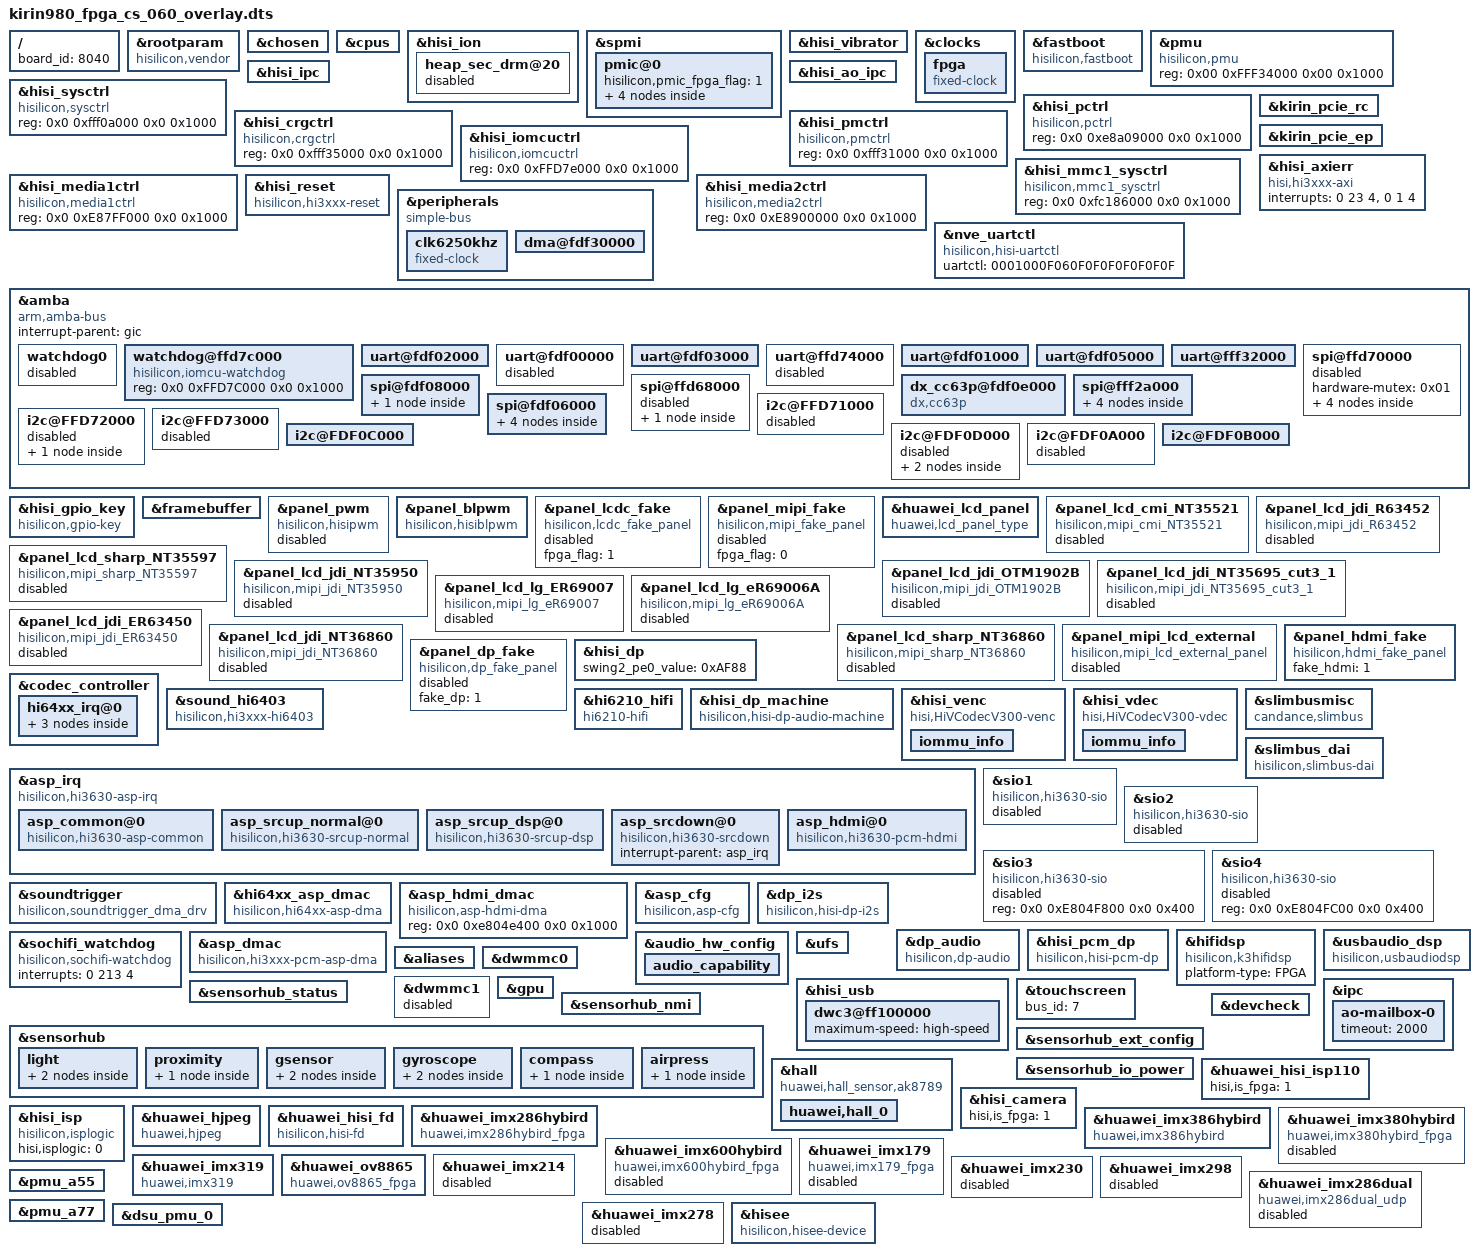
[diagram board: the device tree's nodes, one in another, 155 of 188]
/**
 * Copyright (C) 2014 Hisilicon Ltd.
 *
 *  This program is free software; you can redistribute it and/or modify
 *  it under the terms of the GNU General Public License version 2 as
 *  publishhed by the Free Software Foundation.
 */

/dts-v1/;
/plugin/;
/include/ "kirin980_fpga_cs_060_pin.dtsi"
/include/ "kirin980_fpga_cs_060_modem_pin.dtsi"
/include/ "kirin980_fpga_cs_060_hi6402_pin.dtsi"

/ {
    board_id = <8040>;
};

	&rootparam{
		compatible = "hisilicon,vendor";
		hisi,boardid = <8 0 4 0>;
		hisi,boardname = "kirin980_fpga_cs_060";
		hisi,modem_id = <0x37F5FC00>;
		hisi,product_id = <0x37F5FC10>;
	};

	&chosen{};


	&cpus {
	};

	&hisi_ion {
		heap_sec_drm@20 {
			status = "disabled";
		};
	};

	&spmi {
		pmic@0 {
			hisilicon,pmic_fpga_flag=<1>;
				pmic_led@a0 {
					status = "ok";
				};
				pmic_rtc@a0 {
			       		status = "disabled";
				};
				ponkey@b1{
		           		status = "ok";
				};
				pmic_mntn@a0 {
					status = "disabled";
				};
		};
	};
	&hisi_vibrator {
		status = "ok";
	};

	&clocks {
		fpga {
			compatible = "fixed-clock";
			#clock-cells = <0>;
			clock-frequency = <19200000>;
			clock-output-names = "fpga";
		};
	};

	&fastboot {
		compatible = "hisilicon,fastboot";
		i2c3-pin = <0>;
		gpio-keyup = <147>;
		gpio-keydown = <146>;
		uart-board-type = <1>;
		/*UDP_TYPE 0,PRODUCT 1,FPGA 2,EMU 3*/
		lpm3-board-type = <2>;
		jtagtosd-board-type = <2>;
		motor-vib_type = <0>;

		i2c-select = <1>;
		i2c-sel0-gpio = <164>;
		i2c-sel1-gpio = <165>;
		i2c-sel0-val = <0>;
		i2c-sel1-val = <0>;
	};

	&pmu {
		compatible = "hisilicon,pmu";
		reg = <0x00 0xFFF34000 0x00 0x1000>;
		status = "ok";
	};

	&hisi_ipc {

	};
	&hisi_ao_ipc {

	};

        &hisi_sysctrl {
                compatible = "hisilicon,sysctrl";
                reg = <0x0 0xfff0a000 0x0 0x1000>;
                status = "ok";
        };

        &hisi_pctrl {
                compatible = "hisilicon,pctrl";
                reg = <0x0 0xe8a09000 0x0 0x1000>;
                status = "ok";
        };

        &hisi_crgctrl {
                compatible = "hisilicon,crgctrl";
                reg = <0x0 0xfff35000 0x0 0x1000>;
                status = "ok";
        };

	&hisi_iomcuctrl {
                compatible = "hisilicon,iomcuctrl";
                reg = <0x0 0xFFD7e000 0x0 0x1000>;
                status = "ok";
        };

        &hisi_pmctrl {
                compatible = "hisilicon,pmctrl";
                reg = <0x0 0xfff31000 0x0 0x1000>;
                status = "ok";
        };

        &hisi_mmc1_sysctrl {
                compatible = "hisilicon,mmc1_sysctrl";
                reg = <0x0 0xfc186000 0x0 0x1000>;
                status = "ok";
        };

        &hisi_media1ctrl {
                compatible = "hisilicon,media1ctrl";
                reg = <0x0 0xE87FF000 0x0 0x1000>;
                status = "ok";
        };

        &hisi_media2ctrl {
                compatible = "hisilicon,media2ctrl";
                reg = <0x0 0xE8900000 0x0 0x1000>;
                status = "ok";
        };

	&kirin_pcie_rc {
		wl_power = <63>;

		/* param from EP: for BCM43596  */
		ep_ltr_latency = <0x10031003>;
		ep_l1ss_ctrl2 = <0x61>;
		l1ss_ctrl1 = <0x4004370F>;
		t_ref2perst = <21000 23000>;
		t_perst2access = <7000 8000>;
		t_perst2rst = <10000 11000>;
	};


	&kirin_pcie_ep {
		wl_power = <63>;

		/* param from EP: for BCM43596  */
		ep_ltr_latency = <0x10031003>;
		ep_l1ss_ctrl2 = <0x61>;
		l1ss_ctrl1 = <0x4004370F>;
		t_ref2perst = <21000 23000>;
		t_perst2access = <7000 8000>;
		t_perst2rst = <10000 11000>;
	};

	&hisi_axierr {
	        compatible = "hisi,hi3xxx-axi";
	        interrupts = <0 23 4>, <0 1 4>;
	        status = "ok";
        };

    &hisi_reset {
            compatible = "hisilicon,hi3xxx-reset";
            status = "ok";
        };

	&peripherals {
		compatible = "simple-bus";
		#address-cells = <1>;
		#size-cells = <1>;
		ranges = <0x0 0x00000000 0x0 0xffffffff>;

		clk6250khz {
			compatible = "fixed-clock";
			#clock-cells = <0>;
			clock-frequency = <6297600>;
			clock-output-names = "clk6250khz";
		};
/*
		clk4800khz {
			compatible = "fixed-clock";
			#clock-cells = <0>;
			clock-frequency = <32768>;
			clock-output-names = "clk4800khz";
		};
*/

		dma@fdf30000 {
			status = "ok";
		};


	};
	&nve_uartctl {
		compatible = "hisilicon,hisi-uartctl";
		uartctl = "0001000F060F0F0F0F0F0F0F";
	};
	&amba {
		#address-cells = <2>;
		#size-cells = <2>;
		compatible = "arm,amba-bus";
		interrupt-parent = <&gic>;
		ranges;

		/*rtc@FFF04000 {
				compatible = "arm,rtc-pl031", "arm,primecell";
				reg = <0xfff04000 0x1000>;
				interrupts = <0 46 0x4>;
				clocks = <&pclk>;
				clock-names = "apb_pclk";
				status = "ok";
		};*/

		/*rtc@FFF05000 {
				compatible = "arm,rtc-pl031", "arm,primecell";
				reg = <0xfff05000 0x1000>;
				interrupts = <0 47 0x4>;
				clocks = <&pclk>;
				clock-names = "apb_pclk";
				status = "ok";
		};*/

		watchdog0 {
			status = "disabled";
		};

                watchdog@ffd7c000{
                        compatible = "hisilicon,iomcu-watchdog";
                        reg = <0x0 0xFFD7C000 0x0 0x1000>;
                        status = "ok";
                };

		/*wdt1@e8a07000 {
			compatible = "arm,sp805", "arm,primecell";
			reg = <0x0 0xe8a07000 0x0 0x1000>;
			interrupts = <0 45 4>;
			clocks = <&pclk_gate_wd0 &pclk>;
			clock-names = "pclk_wd0", "apb_pclk";
		};*/

		uart@fdf02000 {
			pinctrl-names = "default", "idle";
			pinctrl-0 = <>;
			pinctrl-1 = <>;
			dma-names = "", "";
			dmas = <>;
			status = "ok";
		};

		uart@fdf00000 {
			pinctrl-names = "default", "idle";
			pinctrl-0 = <>;
			pinctrl-1 = <>;
			reset-enable-flag = <1>;
			status = "disabled";
		};

		uart@fdf03000 {
			pinctrl-names = "default", "idle";
			pinctrl-0 = <>;
			pinctrl-1 = <>;
			reset-enable-flag = <1>;
			status = "ok";
		};

		uart@ffd74000 {
			pinctrl-names = "default", "idle";
			pinctrl-0 = <>;
			pinctrl-1 = <>;
			status = "disabled";
			reset-enable-flag = <0>;
		};

		uart@fdf01000 {
			pinctrl-names = "default", "idle";
			pinctrl-0 = <>;
			pinctrl-1 = <>;
			status = "ok";
			reset-enable-flag = <1>;
		};

		uart@fdf05000 {
			pinctrl-names = "default", "idle";
			pinctrl-0 = <>;
			pinctrl-1 = <>;
			status = "ok";
			reset-enable-flag = <1>;
		};

		uart@fff32000 {
			pinctrl-names = "default", "idle";
			pinctrl-0 = <>;
			pinctrl-1 = <>;
			status = "ok";
		};

		dx_cc63p@fdf0e000 {
			compatible = "dx,cc63p";
			reg = <0x0 0xfdf0e000 0x0 0x1000>;
			interrupt-parent = <&gic>;
			interrupts = <0 135 4>;
			status = "ok";
		};

		spi@ffd70000 {
			status = "disabled";
			hardware-mutex = <0x01>;
			spi_dev0@0 {
					compatible = "spi_dev0";
					spi-max-frequency = <100000>;
					reg = <0>;
					pl022,com-mode = <0>;
					pl022,interface = <0>;
					pl022,rx-level-trig = <3>;
					pl022,tx-level-trig = <3>;
					pl022,ctrl-len = <7>;
					pl022,wait-state = <0>;
					pl022,duplex = <0>;
					pl022,slave-tx-disable = <0>;
			};

			spi_dev1@1 {
					compatible = "spi_dev1";
					spi-max-frequency = <13000000>;
					reg = <1>;
					pl022,com-mode = <1>;
					pl022,interface = <0>;
					pl022,rx-level-trig = <3>;
					pl022,tx-level-trig = <3>;
					pl022,ctrl-len = <7>;
					pl022,wait-state = <0>;
					pl022,duplex = <0>;
					pl022,slave-tx-disable = <0>;
			};

			spi_dev2@2 {
					compatible = "spi_dev2";
					spi-max-frequency = <13000000>;
					reg = <2>;
					pl022,com-mode = <2>;
					pl022,interface = <0>;
					pl022,rx-level-trig = <3>;
					pl022,tx-level-trig = <3>;
					pl022,ctrl-len = <7>;
					pl022,wait-state = <0>;
					pl022,duplex = <0>;
					pl022,slave-tx-disable = <0>;
			};

			spi_dev3@3 {
					compatible = "spi_dev3";
					spi-max-frequency = <13000000>;
					reg = <3>;
					pl022,com-mode = <0>;
					pl022,interface = <0>;
					pl022,rx-level-trig = <3>;
					pl022,tx-level-trig = <3>;
					pl022,ctrl-len = <7>;
					pl022,wait-state = <0>;
					pl022,duplex = <0>;
					pl022,slave-tx-disable = <0>;
			};
		};

		spi@fdf08000 {
			status = "ok";
			spi_dev10@10 {
					compatible = "spi_dev10";
					spi-max-frequency = <100000>;
					reg = <0>;
					pl022,com-mode = <0>;
					pl022,interface = <0>;
					pl022,rx-level-trig = <3>;
					pl022,tx-level-trig = <3>;
					pl022,ctrl-len = <7>;
					pl022,wait-state = <0>;
					pl022,duplex = <0>;
					pl022,slave-tx-disable = <0>;
			};
		};
		spi@ffd68000 {
			status = "disabled";
			spi_dev20@20 {
					compatible = "spi_dev20";
					spi-max-frequency = <100000>;
					reg = <0>;
					pl022,com-mode = <1>;
					pl022,interface = <0>;
					pl022,rx-level-trig = <3>;
					pl022,tx-level-trig = <3>;
					pl022,ctrl-len = <7>;
					pl022,wait-state = <0>;
					pl022,duplex = <0>;
					pl022,slave-tx-disable = <0>;
			};
		};

		spi@fff2a000 {
			status = "ok";
			spi_dev30@30 {
					compatible = "spi_dev30";
					spi-max-frequency = <100000>;
					reg = <0>;
					pl022,com-mode = <0>;
					pl022,interface = <0>;
					pl022,rx-level-trig = <3>;
					pl022,tx-level-trig = <3>;
					pl022,ctrl-len = <7>;
					pl022,wait-state = <0>;
					pl022,duplex = <0>;
					pl022,slave-tx-disable = <0>;
			};

			spi_dev31@31 {
					compatible = "spi_dev31";
					spi-max-frequency = <13000000>;
					reg = <1>;
					pl022,com-mode = <1>;
					pl022,interface = <0>;
					pl022,rx-level-trig = <3>;
					pl022,tx-level-trig = <3>;
					pl022,ctrl-len = <7>;
					pl022,wait-state = <0>;
					pl022,duplex = <0>;
					pl022,slave-tx-disable = <0>;
			};

			spi_dev32@32 {
					compatible = "spi_dev32";
					spi-max-frequency = <13000000>;
					reg = <2>;
					pl022,com-mode = <2>;
					pl022,interface = <0>;
					pl022,rx-level-trig = <3>;
					pl022,tx-level-trig = <3>;
					pl022,ctrl-len = <7>;
					pl022,wait-state = <0>;
					pl022,duplex = <0>;
					pl022,slave-tx-disable = <0>;
			};

			spi_dev33@33 {
					compatible = "spi_dev33";
					spi-max-frequency = <13000000>;
					reg = <3>;
					pl022,com-mode = <0>;
					pl022,interface = <0>;
					pl022,rx-level-trig = <3>;
					pl022,tx-level-trig = <3>;
					pl022,ctrl-len = <7>;
					pl022,wait-state = <0>;
					pl022,duplex = <0>;
					pl022,slave-tx-disable = <0>;
			};
		};
		spi@fdf06000 {
			status = "ok";
			spi_dev40@40 {
					compatible = "spi_dev40";
					spi-max-frequency = <100000>;
					reg = <0>;
					pl022,com-mode = <0>;
					pl022,interface = <0>;
					pl022,rx-level-trig = <3>;
					pl022,tx-level-trig = <3>;
					pl022,ctrl-len = <7>;
					pl022,wait-state = <0>;
					pl022,duplex = <0>;
					pl022,slave-tx-disable = <0>;
			};

			spi_dev41@41 {
					compatible = "spi_dev41";
					spi-max-frequency = <13000000>;
					reg = <1>;
					pl022,com-mode = <1>;
					pl022,interface = <0>;
					pl022,rx-level-trig = <3>;
					pl022,tx-level-trig = <3>;
					pl022,ctrl-len = <7>;
					pl022,wait-state = <0>;
					pl022,duplex = <0>;
					pl022,slave-tx-disable = <0>;
			};

			spi_dev42@42 {
					compatible = "spi_dev42";
					spi-max-frequency = <13000000>;
					reg = <2>;
					pl022,com-mode = <2>;
					pl022,interface = <0>;
					pl022,rx-level-trig = <3>;
					pl022,tx-level-trig = <3>;
					pl022,ctrl-len = <7>;
					pl022,wait-state = <0>;
					pl022,duplex = <0>;
					pl022,slave-tx-disable = <0>;
			};

			spi_dev43@43 {
					compatible = "spi_dev43";
					spi-max-frequency = <13000000>;
					reg = <3>;
					pl022,com-mode = <0>;
					pl022,interface = <0>;
					pl022,rx-level-trig = <3>;
					pl022,tx-level-trig = <3>;
					pl022,ctrl-len = <7>;
					pl022,wait-state = <0>;
					pl022,duplex = <0>;
					pl022,slave-tx-disable = <0>;
			};
		};
		/* I2C0 ~ I2C4 */
		i2c@FFD71000 {
			status = "disabled";
			pinctrl-names = "default", "idle";
			pinctrl-0 = <>;
			pinctrl-1 = <>;
			//cs-gpios = <>, <>;
		};

		i2c@FFD72000 {
			status = "disabled";
			clock-rate = <0 32000000>;
			pinctrl-names = "default", "idle";
			pinctrl-0 = <>;
			pinctrl-1 = <>;
			//cs-gpios = <>, <>;

			hisi,ncp6925@50{
				compatible = "hisi,ncp6925";
				reg = <0x50>;
				hisi,pmic_name = "ncp6925";
				hisi,pmic_index = <0>;
				hisi,slave_address = <0x50>;
				hisi,pmic-pin = <999 999 999>;
				hisi,pmic-voltage = <0x0 0x1 0x2 0x3 0x4 0x5 0x6>;
				hisi,pmic_ex_func_disable = <1>;
				status = "disabled";
			};
		};

		i2c@FFD73000 {
			status = "disabled";
			clock-rate = <0 32000000>;
			pinctrl-names = "default", "idle";
			pinctrl-0 = <>;
			pinctrl-1 = <>;
			//cs-gpios = <>, <>;
		};

		i2c@FDF0C000 {
			status = "ok";
			clock-rate = <0 20000000>;
			pinctrl-names = "default", "idle";
			pinctrl-0 = <>;
			pinctrl-1 = <>;
			//cs-gpios = <>, <>;
		};

		i2c@FDF0D000 {
			status = "disabled";
			clock-rate = <0 107000000>;
			pinctrl-names = "default", "idle";
			pinctrl-0 = <>;
			pinctrl-1 = <>;
			//cs-gpios = <>, <>;

			smartpa@31 {
				status = "ok";
				gain_incall = <0x16>;
				gain = <0x16>;
			};

			smartpa@34 {
				status = "ok";
				gain_incall = <0x16>;
				gain = <0x16>;
			};

		};

		i2c@FDF0A000 {
			status = "disabled";
			clock-rate = <0 107000000>;
			pinctrl-names = "default", "idle";
			pinctrl-0 = <>;
			pinctrl-1 = <>;
			//cs-gpios = <>, <>;
		};

		i2c@FDF0B000 {
			status = "ok";
			clock-rate = <0 107000000>;
			pinctrl-names = "default", "idle";
			pinctrl-0 = <&gpio191_pmx_func &gpio192_pmx_func &gpio191_cfg_func &gpio192_cfg_func>;
			pinctrl-1 = <&gpio191_pmx_idle &gpio192_pmx_idle &gpio191_cfg_idle &gpio192_cfg_idle>;
			cs-gpios = <&gpio23 7 0>, <&gpio24 0 0>;
		};
	};
	/* end amba */

	&hisi_gpio_key {
		compatible = "hisilicon,gpio-key";
		pinctrl-names = "default", "idle";
		pinctrl-0 = <>;
		pinctrl-1 = <>;
		gpio-keyup,gpio-irq = <&gpio18 3 0>;
		gpio-keydown,gpio-irq = <&gpio18 2 0>;
		status = "ok";
	};

	/* display start */
	&framebuffer {
		fpga_flag = <1>;
		//FB_ACCEL_KIRIN970_ES  0x20;FB_ACCEL_KIRIN970  0x40;
		dss_version_tag = <0x100>;
	};

	&panel_pwm {
		#address-cells = <2>;
		#size-cells = <2>;
		compatible = "hisilicon,hisipwm";
		reg = <0 0xE8A04000 0 0x1000>;
		clocks = <&clk_gate_pwm>;
		clock-names = "clk_pwm";
		//pinctrl-names = "default","idle";
		//pinctrl-0 = <&gpio182_pmx_func &gpio182_cfg_func>;
		//pinctrl-1 = <&gpio182_pmx_idle &gpio182_cfg_idle>;
		fpga_flag = <1>;
		status = "disabled";
	};

	&panel_blpwm {
		#address-cells = <2>;
		#size-cells = <2>;
		compatible = "hisilicon,hisiblpwm";
		reg = <0 0xFFD75000 0 0x1000>;
		clocks = <&clk_gate_blpwm>;
		clock-names = "clk_blpwm";
		pinctrl-names = "default","idle";
		pinctrl-0 = <&gpio181_pmx_func &gpio182_pmx_func &gpio181_cfg_func &gpio182_cfg_func>;
		pinctrl-1 = <&gpio181_pmx_idle &gpio182_pmx_idle &gpio181_cfg_idle &gpio182_cfg_idle>;
		fpga_flag = <1>;
		status = "ok";
	};

	&panel_lcdc_fake {
		#address-cells = <2>;
		#size-cells = <2>;
		compatible = "hisilicon,lcdc_fake_panel";
		fpga_flag = <1>;
		status = "disabled";
	};

	&panel_mipi_fake {
		#address-cells = <2>;
		#size-cells = <2>;
		compatible = "hisilicon,mipi_fake_panel";
		fpga_flag = <0>;
		status = "disabled";
	};

	&huawei_lcd_panel {
		compatible = "huawei,lcd_panel_type";
		detect_type = <2>;		/*0:DETECT_GPIOID  1:DETECT_CHIPID  2:DETECT_LCD_TYPE */
		gpio_id = <197>;
		gpio_cfg_addr = <0xFFF11854>;
		//JDI_OTM1902B_LCD, JDI_OTM1906A_LCD, JDI_NT36850_LCD, SHARP_NT35597_LCD
		//AUO_NT35597_LCD, QUNCHUANG_ER63419_LCD, JDI_NT35695_CUT3_1_LCD, JDI_NT35695_LCD ,CMI_NT35521_LCD,LG_ER69006A_LCD
		support_lcd_type = "CMI_NT35521_LCD","JDI_R63452_LCD";
		lcd_id_match_tab = <0 1>;
	};

	&panel_lcd_cmi_NT35521 {
		#address-cells = <2>;
		#size-cells = <2>;
		compatible = "hisilicon,mipi_cmi_NT35521";
		//2:PWM,  4:BLPWM,  8:MIPI
		lcd-bl-type = <8>;
		//8:PANEL_MIPI_VIDEO,  16:PANEL_MIPI_CMD
		lcd-display-type = <8>;
		//0:IFBC_TYPE_NONE
		lcd-ifbc-type = <0>;
		//gpio_lcd_vcc1v8, vsp, vsn, rst, bl_en
		gpios = <&gpio16 2 0>, <&gpio16 0 0>,  <&gpio20 7 0>, <&gpio17 3 0>, <&gpio20 6 0>;
		gpio_nums = <130 128 167 139 166>;
		//lcdio-vcc-supply = <&ldo4>;
		//lcdanalog-vcc-supply = <&ldo17>;
		//pinctrl-names = "default", "idle";
		//pinctrl-0 = <&gpio021_pmx_func &gpio021_cfg_func &gpio009_cfg_func &gpio010_cfg_func &gpio015_cfg_func &gpio020_cfg_func>;
		//pinctrl-1 = <&gpio021_pmx_idle &gpio021_cfg_idle &gpio009_cfg_idle &gpio010_cfg_idle &gpio015_cfg_idle &gpio020_cfg_idle>;
		fpga_flag = <1>;
		status = "disabled";
	};

	&panel_lcd_jdi_R63452 {
		#address-cells = <2>;
		#size-cells = <2>;
		compatible = "hisilicon,mipi_jdi_R63452";
		//2:PWM,  4:BLPWM,  8:MIPI
		lcd-bl-type = <8>;
		//8:PANEL_MIPI_VIDEO,  16:PANEL_MIPI_CMD ,32:PANEL_DUAL_MIPI_VIDEO, 64:PANEL_DUAL_MIPI_CMD
		lcd-display-type = <16>;
		//0:IFBC_TYPE_NONE 7:IFBC_TYPE_VESA3X_SINGLE 9:IFBC_TYPE_VESA3X_DUAL
		lcd-ifbc-type = <0>;
		//UDP: vsp, vsn, lcd_reset, bl_enable, ID0,ID1,TE0: gpio_nums = <12 34 194 11 10 9 16>;
		//vcc1v8, vsp, vsn, rst, bl_en, tp2v85 ,tp1v8
		gpios = <&gpio16 2 0>, <&gpio16 0 0>,  <&gpio20 7 0>, <&gpio17 3 0>, <&gpio20 6 0>, <&gpio17 1 0>, <&gpio16 1 0>;
		//gpio_nums = <130 128 167 139 166>;
		gpio_nums = <130 128 167 139 166 137 129>;

		//lcdio-vcc-supply = <&ldo4>;
		//lcdanalog-vcc-supply = <&ldo17>;
		//pinctrl-names = "default", "idle";
		//pinctrl-0 = <&gpio012_pmx_func &gpio034_pmx_func &gpio194_pmx_func &gpio011_pmx_func &gpio012_cfg_func &gpio034_cfg_func &gpio194_cfg_func &gpio011_cfg_func &gpio010_cfg_func &gpio009_cfg_func>;
		//pinctrl-1 = <&gpio012_pmx_idle &gpio034_pmx_idle &gpio194_pmx_idle &gpio011_pmx_idle &gpio012_cfg_idle &gpio034_cfg_idle &gpio194_cfg_idle &gpio011_cfg_idle &gpio010_cfg_idle &gpio009_cfg_idle>;
		//vsp-vsn-voltage = <15>;
		fpga_flag = <1>;
		status = "disabled";
	};

	&panel_lcd_sharp_NT35597 {
		#address-cells = <2>;
		#size-cells = <2>;
		compatible = "hisilicon,mipi_sharp_NT35597";
		//2:PWM,  4:BLPWM,  8:MIPI
		lcd-bl-type = <8>;
		//8:PANEL_MIPI_VIDEO,  16:PANEL_MIPI_CMD 64:PANEL_DUAL_MIPI_CMD
		lcd-display-type = <64>;
		//0:IFBC_TYPE_NONE 7:IFBC_TYPE_VESA3X_SINGLE 9:IFBC_TYPE_VESA3X_DUAL
		lcd-ifbc-type = <0>;
		//gpio_lcd_vcc1v8, gpio_lcd_p5v5_enable, gpio_lcd_n5v5_enable, gpio_lcd_reset, gpio_lcd_bl_enable, gpio_lcd_tp2v85 ,gpio_lcd_tp1v8
		gpios = <&gpio6 2 0>, <&gpio6 0 0>,  <&gpio8 7 0>, <&gpio7 3 0>, <&gpio8 6 0>, <&gpio7 1 0>, <&gpio6 1 0>;
		gpio_nums = <50 48 71 59 70 57 49>;
		//lcdio-vcc-supply = <&ldo4>;
		//lcdanalog-vcc-supply = <&ldo17>;
		//pinctrl-names = "default", "idle";
		//pinctrl-0 = <&gpio021_pmx_func &gpio021_cfg_func &gpio009_cfg_func &gpio010_cfg_func &gpio015_cfg_func &gpio020_cfg_func>;
		//pinctrl-1 = <&gpio021_pmx_idle &gpio021_cfg_idle &gpio009_cfg_idle &gpio010_cfg_idle &gpio015_cfg_idle &gpio020_cfg_idle>;
		fpga_flag = <1>;
		status = "disabled";
	};

	&panel_lcd_jdi_NT35950 {
		#address-cells = <2>;
		#size-cells = <2>;
		compatible = "hisilicon,mipi_jdi_NT35950";
		//2:PWM,  4:BLPWM,  8:MIPI
		lcd-bl-type = <8>;
		//8:PANEL_MIPI_VIDEO,  16:PANEL_MIPI_CMD , 64:PANEL_DUAL_MIPI_CMD
		lcd-display-type = <64>;
		//0:IFBC_TYPE_NONE 7:IFBC_TYPE_VESA3X_SINGLE 9:IFBC_TYPE_VESA3X_DUAL
		lcd-ifbc-type = <9>;
		//gpio_lcd_vcc1v8, gpio_lcd_p5v5_enable, gpio_lcd_n5v5_enable, gpio_lcd_reset, gpio_lcd_bl_enable, gpio_lcd_tp2v85 ,gpio_lcd_tp1v8
		gpios = <&gpio6 2 0>, <&gpio6 0 0>,  <&gpio8 7 0>, <&gpio7 3 0>, <&gpio8 6 0>, <&gpio7 1 0>, <&gpio6 1 0>;
		gpio_nums = <50 48 71 59 70 57 49>;
		//lcdio-vcc-supply = <&ldo4>;
		//lcdanalog-vcc-supply = <&ldo17>;
		//pinctrl-names = "default", "idle";
		//pinctrl-0 = <&gpio021_pmx_func &gpio021_cfg_func &gpio009_cfg_func &gpio010_cfg_func &gpio015_cfg_func &gpio020_cfg_func>;
		//pinctrl-1 = <&gpio021_pmx_idle &gpio021_cfg_idle &gpio009_cfg_idle &gpio010_cfg_idle &gpio015_cfg_idle &gpio020_cfg_idle>;
		fpga_flag = <1>;
		status = "disabled";
	};
	&panel_lcd_jdi_OTM1902B {
		#address-cells = <2>;
		#size-cells = <2>;
		compatible = "hisilicon,mipi_jdi_OTM1902B";
		//2:PWM,  4:BLPWM,  8:MIPI
		lcd-bl-type = <8>;
		//8:PANEL_MIPI_VIDEO,  16:PANEL_MIPI_CMD
		lcd-display-type = <16>;
		//0:IFBC_TYPE_NONE 7:IFBC_TYPE_VESA3X_SINGLE 9:IFBC_TYPE_VESA3X_DUAL
		lcd-ifbc-type = <0>;
		//gpio_lcd_vcc1v8, gpio_lcd_p5v5_enable, gpio_lcd_n5v5_enable, gpio_lcd_reset, gpio_lcd_bl_enable, gpio_lcd_tp2v85 ,gpio_lcd_tp1v8
		gpios = <&gpio6 2 0>, <&gpio6 0 0>,  <&gpio8 7 0>, <&gpio7 3 0>, <&gpio8 6 0>, <&gpio7 1 0>, <&gpio6 1 0>;
		gpio_nums = <50 48 71 59 70 57 49>;
		//lcdio-vcc-supply = <&ldo4>;
		//lcdanalog-vcc-supply = <&ldo17>;
		//pinctrl-names = "default", "idle";
		//pinctrl-0 = <&gpio021_pmx_func &gpio021_cfg_func &gpio009_cfg_func &gpio010_cfg_func &gpio015_cfg_func &gpio020_cfg_func>;
		//pinctrl-1 = <&gpio021_pmx_idle &gpio021_cfg_idle &gpio009_cfg_idle &gpio010_cfg_idle &gpio015_cfg_idle &gpio020_cfg_idle>;
		fpga_flag = <1>;
		status = "disabled";
	};
	&panel_lcd_jdi_NT35695_cut3_1 {
		#address-cells = <2>;
		#size-cells = <2>;
		compatible = "hisilicon,mipi_jdi_NT35695_cut3_1";
		//2:PWM,  4:BLPWM,  8:MIPI
		lcd-bl-type = <8>;
		//8:PANEL_MIPI_VIDEO,  16:PANEL_MIPI_CMD
		lcd-display-type = <16>;
		//0:IFBC_TYPE_NONE 7:IFBC_TYPE_VESA3X_SINGLE 9:IFBC_TYPE_VESA3X_DUAL
		lcd-ifbc-type = <0>;
		//gpio_lcd_vcc1v8, gpio_lcd_p5v5_enable, gpio_lcd_n5v5_enable, gpio_lcd_reset, gpio_lcd_bl_enable, gpio_lcd_tp2v85 ,gpio_lcd_tp1v8
		gpios = <&gpio16 2 0>, <&gpio16 0 0>,  <&gpio20 7 0>, <&gpio17 3 0>, <&gpio20 6 0>, <&gpio17 1 0>, <&gpio16 1 0>;
		gpio_nums = <130 128 167 139 166 137 129>;
		//lcdio-vcc-supply = <&ldo4>;
		//lcdanalog-vcc-supply = <&ldo17>;
		//pinctrl-names = "default", "idle";
		//pinctrl-0 = <&gpio021_pmx_func &gpio021_cfg_func &gpio009_cfg_func &gpio010_cfg_func &gpio015_cfg_func &gpio020_cfg_func>;
		//pinctrl-1 = <&gpio021_pmx_idle &gpio021_cfg_idle &gpio009_cfg_idle &gpio010_cfg_idle &gpio015_cfg_idle &gpio020_cfg_idle>;
		fpga_flag = <1>;
		status = "disabled";
	};

	&panel_lcd_lg_ER69007 {
		#address-cells = <2>;
		#size-cells = <2>;
		compatible = "hisilicon,mipi_lg_eR69007";
		//2:PWM,  4:BLPWM,  8:MIPI
		lcd-bl-type = <8>;
		//8:PANEL_MIPI_VIDEO,  16:PANEL_MIPI_CMD
		lcd-display-type = <16>;
		//0:IFBC_TYPE_NONE
		lcd-ifbc-type = <0>;
		//gpio_lcd_vcc1v8, gpio_lcd_p5v5_enable, gpio_lcd_n5v5_enable, gpio_lcd_reset, gpio_lcd_bl_enable, gpio_lcd_tp2v85
		gpios = <&gpio6 2 0>, <&gpio6 0 0>,  <&gpio8 7 0>, <&gpio7 3 0>, <&gpio8 6 0> , <&gpio7 1 0>;
		gpio_nums = <50 48 71 59 70 57>;
		//lcdio-vcc-supply = <&ldo4>;
		//lcdanalog-vcc-supply = <&ldo17>;
		//pinctrl-names = "default", "idle";
		//pinctrl-0 = <&gpio021_pmx_func &gpio021_cfg_func &gpio009_cfg_func &gpio010_cfg_func &gpio015_cfg_func &gpio020_cfg_func>;
		//pinctrl-1 = <&gpio021_pmx_idle &gpio021_cfg_idle &gpio009_cfg_idle &gpio010_cfg_idle &gpio015_cfg_idle &gpio020_cfg_idle>;
		fpga_flag = <1>;
		status = "disabled";
	};

	&panel_lcd_lg_eR69006A {
		#address-cells = <2>;
		#size-cells = <2>;
		compatible = "hisilicon,mipi_lg_eR69006A";
		//2:PWM,  4:BLPWM,  8:MIPI
		lcd-bl-type = <8>;
		//8:PANEL_MIPI_VIDEO,  16:PANEL_MIPI_CMD
		lcd-display-type = <16>;
		//0:IFBC_TYPE_NONE
		lcd-ifbc-type = <0>;
		//gpio_lcd_vcc1v8, gpio_lcd_p5v5_enable, gpio_lcd_n5v5_enable, gpio_lcd_reset, gpio_lcd_bl_enable, gpio_lcd_tp2v85 ,gpio_lcd_tp1v8
		gpios = <&gpio16 2 0>, <&gpio16 0 0>,  <&gpio20 7 0>, <&gpio17 3 0>, <&gpio20 6 0>, <&gpio17 1 0>, <&gpio16 1 0>;
		gpio_nums = <130 128 167 139 166 137 129>;
		//lcdio-vcc-supply = <&ldo4>;
		//lcdanalog-vcc-supply = <&ldo17>;
		//pinctrl-names = "default", "idle";
		//pinctrl-0 = <&gpio021_pmx_func &gpio021_cfg_func &gpio009_cfg_func &gpio010_cfg_func &gpio015_cfg_func &gpio020_cfg_func>;
		//pinctrl-1 = <&gpio021_pmx_idle &gpio021_cfg_idle &gpio009_cfg_idle &gpio010_cfg_idle &gpio015_cfg_idle &gpio020_cfg_idle>;
		fpga_flag = <1>;
		status = "disabled";
	};

	&panel_lcd_jdi_ER63450 {
		#address-cells = <2>;
		#size-cells = <2>;
		compatible = "hisilicon,mipi_jdi_ER63450";
		//2:PWM,  4:BLPWM,  8:MIPI
		lcd-bl-type = <8>;
		//8:PANEL_MIPI_VIDEO,  16:PANEL_MIPI_CMD
		lcd-display-type = <16>;
		//0:IFBC_TYPE_NONE 5:IFBC_TYPE_RSP3X 7:IFBC_TYPE_VESA3X_SINGLE 9:IFBC_TYPE_VESA3X_DUAL
		lcd-ifbc-type = <5>;
		//gpio_lcd_vcc1v8, gpio_lcd_p5v5_enable, gpio_lcd_n5v5_enable, gpio_lcd_reset, gpio_lcd_bl_enable, gpio_lcd_tp2v85 ,gpio_lcd_tp1v8
		gpios = <&gpio16 2 0>, <&gpio16 0 0>,  <&gpio20 7 0>, <&gpio17 3 0>, <&gpio20 6 0>, <&gpio17 1 0>, <&gpio16 1 0>;
		gpio_nums = <130 128 167 139 166 137 129>;
		//lcdio-vcc-supply = <&ldo4>;
		//lcdanalog-vcc-supply = <&ldo17>;
		//pinctrl-names = "default", "idle";
		//pinctrl-0 = <&gpio021_pmx_func &gpio021_cfg_func &gpio009_cfg_func &gpio010_cfg_func &gpio015_cfg_func &gpio020_cfg_func>;
		//pinctrl-1 = <&gpio021_pmx_idle &gpio021_cfg_idle &gpio009_cfg_idle &gpio010_cfg_idle &gpio015_cfg_idle &gpio020_cfg_idle>;
		fpga_flag = <1>;
		status = "disabled";
	};
	&panel_lcd_jdi_NT36860 {
		#address-cells = <2>;
		#size-cells = <2>;
		compatible = "hisilicon,mipi_jdi_NT36860";
		//2:PWM,  4:BLPWM,  8:MIPI
		lcd-bl-type = <8>;
		//8:PANEL_MIPI_VIDEO,  16:PANEL_MIPI_CMD
		lcd-display-type = <16>;
		//0:IFBC_TYPE_NONE 7:IFBC_TYPE_VESA3X_SINGLE 9:IFBC_TYPE_VESA3X_DUAL
		lcd-ifbc-type = <0>;
		//gpio_lcd_vcc1v8, gpio_lcd_p5v5_enable, gpio_lcd_n5v5_enable, gpio_lcd_reset, gpio_lcd_bl_enable, gpio_lcd_tp2v85 ,gpio_lcd_tp1v8
		gpios = <&gpio16 2 0>, <&gpio16 0 0>,  <&gpio20 7 0>, <&gpio17 3 0>, <&gpio20 6 0>, <&gpio17 1 0>, <&gpio16 1 0>;
		gpio_nums = <130 128 167 139 166 137 129>;
		//lcdio-vcc-supply = <&ldo4>;
		//lcdanalog-vcc-supply = <&ldo17>;
		//pinctrl-names = "default", "idle";
		//pinctrl-0 = <&gpio021_pmx_func &gpio021_cfg_func &gpio009_cfg_func &gpio010_cfg_func &gpio015_cfg_func &gpio020_cfg_func>;
		//pinctrl-1 = <&gpio021_pmx_idle &gpio021_cfg_idle &gpio009_cfg_idle &gpio010_cfg_idle &gpio015_cfg_idle &gpio020_cfg_idle>;
		fpga_flag = <1>;
		status = "disabled";
	};

	&panel_lcd_sharp_NT36860 {
		#address-cells = <2>;
		#size-cells = <2>;
		compatible = "hisilicon,mipi_sharp_NT36860";
		//2:PWM,  4:BLPWM,  8:MIPI
		lcd-bl-type = <8>;
		//8:PANEL_MIPI_VIDEO,  16:PANEL_MIPI_CMD
		lcd-display-type = <16>;
		//0:IFBC_TYPE_NONE 7:IFBC_TYPE_VESA3X_SINGLE 9:IFBC_TYPE_VESA3X_DUAL
		lcd-ifbc-type = <0>;
		//gpio_lcd_vcc1v8, gpio_lcd_p5v5_enable, gpio_lcd_n5v5_enable, gpio_lcd_reset, gpio_lcd_bl_enable, gpio_lcd_tp2v85 ,gpio_lcd_tp1v8
		gpios = <&gpio16 2 0>, <&gpio16 0 0>,  <&gpio20 7 0>, <&gpio17 3 0>, <&gpio20 6 0>, <&gpio17 1 0>, <&gpio16 1 0>;
		gpio_nums = <130 128 167 139 166 137 129>;
		//lcdio-vcc-supply = <&ldo4>;
		//lcdanalog-vcc-supply = <&ldo17>;
		//pinctrl-names = "default", "idle";
		//pinctrl-0 = <&gpio021_pmx_func &gpio021_cfg_func &gpio009_cfg_func &gpio010_cfg_func &gpio015_cfg_func &gpio020_cfg_func>;
		//pinctrl-1 = <&gpio021_pmx_idle &gpio021_cfg_idle &gpio009_cfg_idle &gpio010_cfg_idle &gpio015_cfg_idle &gpio020_cfg_idle>;
		fpga_flag = <1>;
		status = "disabled";
	};

	&panel_mipi_lcd_external {
		#address-cells = <2>;
		#size-cells = <2>;
		compatible = "hisilicon,mipi_lcd_external_panel";
		//2:PWM,  4:BLPWM,  8:MIPI
		lcd-bl-type = <8>;
		//8:PANEL_MIPI_VIDEO,  16:PANEL_MIPI_CMD
		lcd-display-type = <8>;
		//0:IFBC_TYPE_NONE
		lcd-ifbc-type = <0>;
		//gpio_lcd_vcc1v8, gpio_lcd_p5v5_enable, gpio_lcd_n5v5_enable, gpio_lcd_reset, gpio_lcd_bl_enable, gpio_TP_2V85_EN_B, gpio_TP_1V8_EN_B
		gpios = <&gpio16 3 0>, <&gpio17 0 0>,  <&gpio20 1 0>, <&gpio17 7 0>, <&gpio20 0 0>, <&gpio17 5 0>, <&gpio16 4 0>;
		gpio_nums = <131 136 161 143 160 141 132>;
		//lcdio-vcc-supply = <&ldo4>;
		//lcdanalog-vcc-supply = <&ldo17>;
		//pinctrl-names = "default", "idle";
		//pinctrl-0 = <&gpio021_pmx_func &gpio021_cfg_func &gpio009_cfg_func &gpio010_cfg_func &gpio015_cfg_func &gpio020_cfg_func>;
		//pinctrl-1 = <&gpio021_pmx_idle &gpio021_cfg_idle &gpio009_cfg_idle &gpio010_cfg_idle &gpio015_cfg_idle &gpio020_cfg_idle>;
		fpga_flag = <1>;
		status = "disabled";
	};
	&panel_hdmi_fake {
		#address-cells = <2>;
		#size-cells = <2>;
		compatible = "hisilicon,hdmi_fake_panel";
		fake_hdmi = <1>;
		status = "ok";
	};
	&panel_dp_fake {
		#address-cells = <2>;
		#size-cells = <2>;
		compatible = "hisilicon,dp_fake_panel";
		fake_dp = <1>;
		status = "disabled";
	};

	&hisi_dp {
		swing2_pe0_value = <0xAF88>;
		status = "ok";
	};

	/* display end */

	/* audio device beg */
	&codec_controller {
		gpios = <&gpio4 7 0>; /* GPIO_39 */
		gpio_reset = <56>; /* GPIO_8_0*/
		gpio_codec_ssi = <204>;
		gpio_codec_ssi_func = <1>;
		gpio_ssi_mux = <16>; /* Chicago only */
		slimbusclk_io_driver = <0x7>;
		slimbusdata_io_driver = <0x7>;
		status = "ok";

		hi64xx_irq@0 {
			status = "ok";

			hi6402_codec@0{
				hisilicon,mic_num = <2>;
				status = "disabled";
			};

			hi6403_codec@0{
				hisilicon,mic_num = <2>;
				status = "ok";
			};

			hi6402_pinctrl {
				status = "disabled";
			};
		};
	};

	&sound_hi6403 {
		compatible = "hisilicon,hi3xxx-hi6403";
		status = "ok";
	};

	&hi6210_hifi {
		compatible = "hi6210-hifi";
		status = "ok";
	};

	&hisi_dp_machine {
		compatible = "hisilicon,hisi-dp-audio-machine";
		status = "ok";
	};

  &hisi_venc{
        compatible = "hisi,HiVCodecV300-venc";
        reg = <0x0 0xe8880000 0x0 0x40000>;
        interrupts = <0 296 4>, <0 297 4>, <0 298 4>;
        clocks = <&clk_gate_venc &venc_volt_hold>;
        clock-names = "clk_venc", "venc_volt_hold";
        enc_clk_rate = <600000000>, <400000000>, <277000000>;
        ldo_venc-supply = <&venc>;
        ldo_media-supply = <&venc_fake>;
        venc_qos_mode = <0x2>;
        fpga_flag_es = <1>;
        venc_fpga = <1>;
        status = "ok";
        iommu_info {
            start-addr = <0x40000>;
            size = <0xE0000000>;
        };
      };

  &hisi_vdec {
        compatible = "hisi,HiVCodecV300-vdec";
        reg = <0x0 0xe8800000 0x0 0x40000>;
        interrupts = <0 290 4>, <0 291 4>, <0 292 4>;
        clocks = <&clk_gate_vdec>;
        clock-names = "clk_vdec";
        dec_clk_rate = <480000000>, <332000000>, <207500000>;
        ldo_vdec-supply = <&vdec>;
        ldo_media-supply = <&vdec_fake>;
        vdec_qos_mode = <0x2>;
        fpga_flag_es = <1>;
        vdec_fpga = <1>;
        status = "ok";
        iommu_info {
            start-addr = <0x40000>;
            size = <0xE0000000>;
        };
      };



	&asp_irq {
		compatible = "hisilicon,hi3630-asp-irq";
		reg = <0x0 0xe804e000 0x0 0xa000>;
		#interrupt-cells = <0x2>;
		asp-irq-supply = <&asp>;
		interrupt-controller;
		interrupts = <0x0 0x88 0x4>;
		interrupt-names = "asp_irq";

		asp_common@0 {
			compatible = "hisilicon,hi3630-asp-common";
		};

		asp_srcup_normal@0 {
			compatible = "hisilicon,hi3630-srcup-normal";
			asp-srcup-normal-supply = <&asp>;
			interrupt-parent = <&asp_irq>;
			interrupts = <0x1 0x0>;
			interrupt-names = "asp_srcup_normal";
		};

		asp_srcup_dsp@0 {
			compatible = "hisilicon,hi3630-srcup-dsp";
		};

		asp_srcdown@0 {
			compatible = "hisilicon,hi3630-srcdown";
			interrupt-parent = <&asp_irq>;
		};

		asp_hdmi@0 {
			compatible = "hisilicon,hi3630-pcm-hdmi";
			interrupt-parent = <&asp_irq>;
			interrupts = <0x0 0x0>;
			interrupt-names = "asp_irq_hdmi";
		};
	};
	&slimbusmisc {
		compatible = "candance,slimbus";
		reg = <0x0 0xe8050000 0x0 0xb00>,
			<0x0 0xe804e000 0x0 0xa000>,
			<0x0 0xfff0a000 0x0 0x1000>;
		interrupts = <0x0 0x96 0x4>;
		interrupt-names = "asp_irq_slimbus";
		slimbus-reg-supply = <&asp>;
		pinctrl-names = "default", "idle";
		pinctrl-0 = <>;
		pinctrl-1 = <>;
		slimbus-ssi-sel = "slimbus";
		asp_power_state_offset = <0x06c>;
		slimbusclk_offset = <0x034>;
		slimbusdata_offset = <0x038>;
		slimbusclk_cfg_offset = <0x85C>;
		slimbusdata_cfg_offset = <0x860>;
		platform-type   = "FPGA";
		codec-type = "slimbus-6403cs";
		clk_asp_subsys = <533000>;
		status = "ok";
	};
	&slimbus_dai {
		compatible = "hisilicon,slimbus-dai";
		status = "ok";
	};

	&sio1 {
		compatible = "hisilicon,hi3630-sio";
		reg = <0x0 0xE804F000 0x0 0x400>;
		sio-audio-supply = <&asp>;
		/* wbd
		pinctrl-names = "default", "idle";
		pinctrl-0 = <&gpio183_pmx_func
				    &gpio184_pmx_func
				    &gpio185_pmx_func
				    &gpio186_pmx_func
				    &gpio183_cfg_func
				    &gpio184_cfg_func
				    &gpio185_cfg_func
				     &gpio186_cfg_func>;
		pinctrl-1 = <&gpio183_pmx_idle
				    &gpio184_pmx_idle
				    &gpio185_pmx_idle
				    &gpio186_pmx_idle
				    &gpio183_cfg_idle
				    &gpio184_cfg_idle
				    &gpio185_cfg_idle
				    &gpio186_cfg_idle>;
		*/
		status = "disabled";
	};

	&sio2 {
		compatible = "hisilicon,hi3630-sio";
		reg = <0x0 0xE804F400 0x0 0x400>;
		sio-voice-supply = <&asp>;
		/* wbd
		pinctrl-names = "default", "idle";
		pinctrl-0 = <&gpio043_pmx_func
				     &gpio044_pmx_func
				     &gpio045_pmx_func
				     &gpio046_pmx_func
				     &gpio043_cfg_func
				     &gpio044_cfg_func
				     &gpio045_cfg_func
				     &gpio046_cfg_func>;
			pinctrl-1 = <&gpio043_pmx_idle
				     &gpio044_pmx_idle
				     &gpio045_pmx_idle
				     &gpio046_pmx_idle
				     &gpio043_cfg_idle
				     &gpio044_cfg_idle
				     &gpio045_cfg_idle
				     &gpio046_cfg_idle>;
		*/
		status = "disabled";
	};

	&sio3 {
		compatible = "hisilicon,hi3630-sio";
		reg = <0x0 0xE804F800 0x0 0x400>;
		status = "disabled";
	};

	&sio4 {
		compatible = "hisilicon,hi3630-sio";
		reg = <0x0 0xE804FC00 0x0 0x400>;
		status = "disabled";
	};

	&soundtrigger {
		compatible = "hisilicon,soundtrigger_dma_drv";
		reg = <0x0 0xe804b000 0x0 0x1000>;
		asp-dmac-supply = <&asp>;
		status = "ok";
	};

	&hi64xx_asp_dmac {
		compatible = "hisilicon,hi64xx-asp-dma";
		reg = <0x0 0xe804b000 0x0 0x1000>;
		asp-dmac-supply = <&asp>;
		interrupts = <0 216 4>;
		interrupt-names = "asp_dma_irq";
		status = "ok";
	};

	&asp_hdmi_dmac {
		compatible = "hisilicon,asp-hdmi-dma";
		reg = <0x0 0xe804e400 0x0 0x1000>;
		status = "ok";
	};

	&asp_cfg {
		compatible = "hisilicon,asp-cfg";
		reg = <0x0 0xe804e000 0x0 0xa000>;
		asp-supply = <&asp>;
		status = "ok";
	};

	&dp_i2s {
		compatible = "hisilicon,hisi-dp-i2s";
		status = "ok";
        };

	&dp_audio {
		compatible = "hisilicon,dp-audio";
		status = "ok";
        };

	&hisi_pcm_dp {
		compatible = "hisilicon,hisi-pcm-dp";
		interrupts = <0x0 0x96 0x4>;
		interrupt-names = "asp_hdmi_dma";
		dp-pcm-supply = <&asp>;
		status = "ok";
	};

	&hifidsp {
			compatible = "hisilicon,k3hifidsp";
			status = "ok";
			platform-type = "FPGA";
	};

	&sochifi_watchdog {
		compatible = "hisilicon,sochifi-watchdog";
		interrupts = <0 213 4>;
		status = "ok";
	};

	&asp_dmac {
		compatible = "hisilicon,hi3xxx-pcm-asp-dma";
		reg = <0x0 0xe804b000 0x0 0x1000>;
		asp-dmac-supply = <&asp>;
		status = "ok";
	};

	&usbaudio_dsp {
		compatible = "hisilicon,usbaudiodsp";
		status = "ok";
	};

	&audio_hw_config {
		product_name = "kirin980FPGA";
		spk_pa_name = "max98925";
		cust_name = "audio_custom";
		soc_name = "hi363x";
		codec_name = "hi6403";
		codec_dsp_algo = "maxim|mad";
		modem_sio_master = "false";
		ear_pa_name = "max98925";
		status = "ok";
		audio_capability {
			bwe_ui_support = "false";
			bwe_support = "true";
			swb_support = "true";
			wnr_support = "false";
			nv_evs_support = "true";
			lvm_support = "false";
			dhf_support = "false";
			dual_smartpa_support = "true";
			spk_rcv_stereo_support = "true";
			asr_vibrate_support = "true";
		};
	};
	/* audio device end */

	/* UFS */
	&ufs {
		status = "ok";
	};

	/* rename eMMC,SD,SDIO */
	&aliases {
	};

	/* eMMC 4.5 */
	&dwmmc0 {
		status = "ok";
	};

	/* SD */
	&dwmmc1 {
		status = "disabled";
	};

	/* wifi */
	/*
	&dwmmc2 {
		status = "disabled";
	};
	*/

	&hisi_usb {
		fpga_flag = <1>;
		bc_again_flag = <0>;
		fpga_phy_reset_gpio = <&gpio1 7 0>;
		fpga_phy_switch_gpio = <&gpio22 1 0>;
		fpga_otg_drv_vbus_gpio = <&gpio0 0 0>;
			dwc3@ff100000 {
				maximum-speed = "high-speed";
			};
	};
	&gpu {
		fpga-gpu-exist = <1>;
		gpu_outstanding = <0x9000000>;
		status = "ok";
	};

	&touchscreen {
		bus_id = <7>;
		status = "ok";
	};

	&sensorhub_status{
	};

	&ipc {	/* add for fpga because iom7 start too slow */
		ao-mailbox-0 {
			timeout = <2000>;
		};
	};

	&sensorhub_nmi{
	};

	&sensorhub{
		#address-cells=<1>;
		#size-cells=<0>;
		light{
			als1{
				compatible="huawei,rohm_bh1745";
				reg=<0x38>;
				chip_id_value=<0xE0>;
				file_id=<38>;
				poll_interval=<350>;
				gpio_int1=<&gpio26 6 0>;
				als_phone_type = <11>;
				als_phone_version = <10>;
				als_extend_data = <0 0 0 0 0 0 0 0 0 0 0 0>;
			};
			als2{
				compatible="huawei,avago_apds9251";
				bus_number = <0x0>;
				reg=<0x52>;
				chip_id_register = <0x06>;
				chip_id_value = <0xB2>;
				file_id = <41>;
				sensor_list_info_id = <0x19>;
				sensor_type = "als";
				poll_interval = <120>;
				threshold_value = <0x1>;
				GA1 = <0x1046>;
				GA2 = <0xf3c>;
				GA3 = <0x1194>;
				tp_color = <0x0>;
				again = <0x1>;
				gpio_int1 = <0x38 0x6 0x0>;
				atime = <0xdb>;
				init_time = <0x96>;
				status = "disabled";
				als_phone_type = <11>;
				als_phone_version = <11>;
				als_extend_data = <0x0 0x0 0x0 0x0 0x0 0x0 0x0 0x0 0x0 0x0 0x0 0x0>;
			};
		};

		proximity{
			ps1{
				compatible="huawei,txc-pa224";
				reg=<0x1e>;
				chip_id_register=<0x7F>;
				chip_id_value=<0x11>;
				file_id=<39>;
				min_proximity_value=<220>;
				pwindows_value=<14>;
				pwave_value=<12>;
				threshold_value=<25>;
				gpio_int1=<&gpio27 1 0>;
				poll_interval = <30>;
			};

		};
		gsensor{
			acc1{
				compatible="huawei,bosch-bmi160";
				reg=<0x68>;
				chip_id_register=<0x0>;
				chip_id_value=<0xd1>;
				file_id=<33>;
				axis_map_x=<1>;
				axis_map_y=<0>;
				axis_map_z=<2>;
				negate_x=<1>;
				negate_y=<1>;
				negate_z=<1>;
				offset_x=<0>;
				offset_y=<0>;
				offset_z=<0>;
				sensitivity_x=<1>;
				sensitivity_y=<1>;
				sensitivity_z=<1>;
				gpio_int2=<&gpio26 5 0>;
				calibrate_style=<0>;
				status = "ok";
			};
			acc2{
				compatible="huawei,st-lsm6ds3";
				bus_number=<0>;
				reg=<0x6a>;
				chip_id_register=<0x0f>;
				chip_id_value=<0x69>;
				file_id=<34>;
				sensor_list_info_id=<0>;
				sensor_type="acc";
				/*sensor-vdd-supply = <&ldo24>;*/
				axis_map_x=<0>;
				axis_map_y=<1>;
				axis_map_z=<2>;
				negate_x=<0>;
				negate_y=<1>;
				negate_z=<1>;
				offset_x=<0>;
				offset_y=<0>;
				offset_z=<0>;
				sensitivity_x=<1>;
				sensitivity_y=<1>;
				sensitivity_z=<1>;
				poll_interval=<10>;
				gpio_int1=<&gpio26 0 0>;
				gpio_int2=<&gpio26 5 0>;
				calibrate_style=<0>;
				status = "ok";
			};
		};

		gyroscope{
			gyro1{
				compatible ="huawei,bosch-bmi160";
				reg=<0x68>;
				chip_id_register=<0x0>;
				chip_id_value=<0xd1>;
				file_id=<35>;
				axis_map_x=<1>;
				axis_map_y=<0>;
				axis_map_z=<2>;
				negate_x=<1>;
				negate_y=<1>;
				negate_z=<1>;
				gpio_int2=<&gpio26 5 0>;
				status = "ok";
			};
			gyro2{
				compatible ="huawei,st-lsm6ds3";
				bus_number=<0>;
				reg=<0x6a>;
				chip_id_register=<0x0f>;
				chip_id_value=<0x69>;
				file_id=<36>;
				sensor_list_info_id=<5>;
				sensor_type="gyro";
				/*sensor-vdd-supply = <&ldo24>;*/
				axis_map_x=<0>;
				axis_map_y=<1>;
				axis_map_z=<2>;
				negate_x=<0>;
				negate_y=<1>;
				negate_z=<1>;
				poll_interval=<10>;
				gpio_int1=<&gpio26 2 0>;
				gpio_int2=<&gpio26 5 0>;
				status = "ok";
			};
		};
		compass{
			mag1{
				compatible="huawei,akm-akm09911";
				bus_number=<0>;
				reg=<0x0c>;
				chip_id_register=<0x00>;
				chip_id_value=<0x48>;
				file_id=<37>;
				sensor_list_info_id=<1>;
				sensor_type="mag";
				/*sensor-vdd-supply = <&ldo24>;*/
				outbit=<0>;
				calibrate_method=<2>;
				axis_map_x=<1>;
				axis_map_y=<0>;
				axis_map_z=<2>;
				negate_x=<1>;
				negate_y=<0>;
				negate_z=<0>;
				poll_interval=<10>;
				gpio_int1=<&gpio0 0 0>;
				gpio_reset=<&gpio0 0 0>;
				softiron_parameter = <13 39 19 255 59 00 19 255 59 41 221 255 59 00 221 255 102 42 0 0 0 0 0 0 0 0 0>;
				status = "ok";
			};
		};
		airpress{
			airpress1{
				compatible="huawei,rohm_bm1383";
				bus_number=<0>;
				reg=<0x5D>;
				chip_id_register=<0x10>;
				chip_id_value=<0x31>;
				file_id=<40>;
				sensor_list_info_id=<0xF>;
				sensor_type="airpress";
				poll_interval = <500>;
				status = "ok";
			};
		};
	};

	&sensorhub_ext_config {
		adapt_sensor_list_id = <0x2 0x6 0x7 0x8 0x9 0xa 0x1a 0x1b 0x1c 0x22>;
		adapt_file_id = <14>;
	};

	&sensorhub_io_power{
	};

	&hall {
		compatible = "huawei,hall_sensor,ak8789";
		status = "ok";
		huawei,hall_0{
			huawei,single-n-pole = <&gpio23 1 0>;
			huawei,type = <0x01>;
			huawei,default-state = "on";
		};
	};
	/*
		device check : the 0 means that it don't need to check;
			the 1 means that it check at board check and running test;
			the 2 means that it check at running test
	*/
	&devcheck {
		touch_panel = <2>;
		compass = <1>;
		g_sensor = <1>;
		gyroscope = <1>;
		nfc = <1>;
		dc_dc = <1>;
		tps = <1>;
		l_sensor = <2>;
		charge = <1>;
		usb_switch = <1>;
		wifi = <1>;
		bt = <1>;
		gps = <1>;
		antenna_ctl = <0>;
		airpress = <1>;
		vibrator_lra = <1>;
		status = "ok";
	};

	&huawei_hisi_isp110 {
		hisi,is_fpga = <1>;
	};

	&hisi_camera {
		hisi,is_fpga = <1>;
	};

	&hisi_isp{
		compatible = "hisilicon,isplogic";
		hisi,isplogic = <0>;
	};

	&huawei_hjpeg {
		compatible = "huawei,hjpeg";
		huawei,hjpeg-base = <0xE8300000 0x1000>;
		huawei,smmu-base = <0xE8320000 0x20000>;
		huawei,cvdr-base = <0xE8306000 0x2000>;
		huawei,subctrl-base = <0xE8304000 0x4>;
		huawei,chip_type = <1>;
		huawei,smmu_bypass = <0>;
		huawei,smmu_type = <1>;
		huawei,power_control = <0>;
		huawei,cvdr = <0 4 25>;
		huawei,stream_id = <0 4 5>;
		huawei,qos_update = <1>;
		huawei,iova_update = <1>;
		huawei,wr_port_addr_update = <1>;
		clocks = <&clk_gate_jpg_func>;
		clock-names = "clk_jpg_func";
		clock-value = <600000000>;
		clock-low-frequency = <277000000>;
		power-off-frequency = <277000000>;

		reg = <0 0xE8300000 0 0x1000>;
		interrupts = <0 299 4>;
		hjpeg-srt-supply = <&ispsubsys>;
		hjpeg-media-supply = <&media1_subsys>;
		status = "ok";
	};

	&huawei_hisi_fd {
		compatible = "hisilicon,hisi-fd";
		reg = <0x0 0xE8340000 0x0 0x20000>,    //FD reg
		      <0x0 0xE8320000 0x0 0x20000>,    //smmu reg
		      <0x0 0xE8303000 0x0 0x1000>;     //smmu master reg
		huawei,top-base = <0xE8304000 0x1000>;
		hisi-fd-supply = <&ispsubsys>;
		hisi-media-supply = <&media1_subsys>;
		clocks = <&clk_gate_fd_func &clk_gate_jpg_func>;
		clock-names = "clk_fd_func", "clk_jpg_func";
		clock-value = <384000000>;
		clock-low-frequency = <277000000>;
		interrupts = <0 307 4>;
		huawei,smmu-flag = <1>;
		huawei,ram-config = <1>;
		smmu_offset_list = <0x10 0x1c 0x20 0x204 0x20c 0x220 0x224>;
		mstr_offset_list = <0x28 0x34 0x100 0x260 0x3c0>;
		fd_offset_list = <0x418 0x40c 0x410 0x414 0x464 0xFD 0x7A 0x9F 0x58 0x31c 0x470>;
		status = "ok";
	};

	&huawei_imx286hybird {
		compatible = "huawei,imx286hybird_fpga";
		huawei,sensor_name = "IMX286HYBIRD_FPGA";
		huawei,sensor_index = <0>;
		huawei,is_fpga = <1>;
		huawei,pd_valid = <1>;
		huawei,reset_valid = <1>;
		huawei,vcmpd_valid = <0>;
		huawei,csi_index = <0 2>;
		huawei,i2c_index = <0 2>;
		gpios = <&gpio11 3 0 &gpio11 1 0 &gpio10 7 0 &gpio11 0 0 &gpio10 6 0 &gpio10 5 0 &gpio10 2 0 &gpio10 4 0 &gpio10 3 0 &gpio11 2 0>;
		huawei,gpio-ctrl-types = "reset", "powerdown", "dphy_txrxz", "dphy_rstzcal", "cam_1v05_en", "cam_1v2_en", "cam_1v8_en", "cam_2v85_en", "cam_vcm_2v85_en", "cam_vcm_power";
		status = "ok";
	};

	&huawei_imx386hybird {
		compatible = "huawei,imx386hybird";
		huawei,sensor_name = "IMX386HYBIRD_FPGA";
		huawei,sensor_index = <0>;
		huawei,is_fpga = <1>;
		huawei,pd_valid = <1>;
		huawei,reset_valid = <1>;
		huawei,vcmpd_valid = <0>;
		huawei,csi_index = <0 2>;
		huawei,i2c_index = <0 2>;
		gpios = <&gpio11 3 0 &gpio11 1 0 &gpio10 7 0 &gpio11 0 0 &gpio10 6 0 &gpio10 5 0 &gpio10 2 0 &gpio10 4 0 &gpio10 3 0 &gpio11 2 0>;
		huawei,gpio-ctrl-types = "reset", "powerdown", "dphy_txrxz", "dphy_rstzcal", "cam_1v05_en", "cam_1v2_en", "cam_1v8_en", "cam_2v85_en", "cam_vcm_2v85_en", "cam_vcm_power";
		status = "ok";
	};

	&huawei_imx380hybird {
		compatible = "huawei,imx380hybird_fpga";
		huawei,sensor_name = "IMX380HYBIRD_FPGA";
		huawei,sensor_index = <0>;
		huawei,is_fpga = <1>;
		huawei,pd_valid = <1>;
		huawei,reset_valid = <1>;
		huawei,vcmpd_valid = <0>;
		huawei,csi_index = <0 2>;
		huawei,i2c_index = <0 2>;
		gpios = <&gpio10 1 0 &gpio10 2 0 &gpio10 3 0 &gpio10 4 0>;
		huawei,gpio-ctrl-types = "reset", "reset2", "ldo_en", "suspend";
		status = "disabled";
	};

	&huawei_imx600hybird {
		compatible = "huawei,imx600hybird_fpga";
		huawei,sensor_name = "IMX600HYBIRD_FPGA";
		huawei,sensor_index = <0>;
		huawei,is_fpga = <1>;
		huawei,pd_valid = <1>;
		huawei,reset_valid = <1>;
		huawei,vcmpd_valid = <0>;
		huawei,csi_index = <0 2>;
		huawei,i2c_index = <0 2>;
		gpios = <&gpio10 1 0 &gpio10 2 0 &gpio10 3 0 &gpio10 4 0>;
		huawei,gpio-ctrl-types = "reset", "reset2", "ldo_en", "suspend";
		status = "disabled";
	};

	&huawei_imx179 {
        compatible = "huawei,imx179_fpga";
        huawei,sensor_name = "IMX179_4L_FOXCONN_FPGA";
		huawei,is_fpga = <1>;
		huawei,csi_index = <1>;
		huawei,i2c_index = <1>;
        gpios = <&gpio12 7 0 &gpio12 5 0 &gpio12 3 0 &gpio12 4 0 &gpio12 2 0 &gpio12 1 0 &gpio11 6 0 &gpio12 0 0 &gpio11 7 0 &gpio12 6 0>;
        huawei,gpio-ctrl-types = "reset", "powerdown", "dphy_txrxz", "dphy_rstzcal", "cam_1v05_en", "cam_1v2_en", "cam_1v8_en", "cam_2v85_en", "cam_vcm_2v85_en", "cam_vcm_power";
		status = "disable";
	};

	&huawei_imx319 {
		compatible = "huawei,imx319";
		huawei,sensor_name = "IMX319_FPGA";
		huawei,is_fpga = <1>;
		huawei,pd_valid = <1>;
		huawei,sensor_index = <1>;
		huawei,csi_index = <1>;
		huawei,i2c_index = <1>;
		huawei,reset_valid = <1>;
		huawei,vcmpd_valid = <0>;

        gpios = <&gpio12 7 0 &gpio12 5 0 &gpio12 3 0 &gpio12 4 0 &gpio12 2 0 &gpio12 1 0 &gpio11 6 0 &gpio12 0 0 &gpio11 7 0 &gpio12 6 0>;
        huawei,gpio-ctrl-types = "reset", "powerdown", "dphy_txrxz", "dphy_rstzcal", "cam_1v05_en", "cam_1v2_en", "cam_1v8_en", "cam_2v85_en", "cam_vcm_2v85_en", "cam_vcm_power";
		status = "ok";
	};

	&huawei_ov8865 {
		compatible = "huawei,ov8865_fpga";
		huawei,sensor_name = "OV8865_FPGA";
		huawei,is_fpga = <1>;
		huawei,pd_valid = <1>;
		huawei,sensor_index = <1>;
		huawei,csi_index = <1>;
		huawei,i2c_index = <1>;
		huawei,reset_valid = <1>;
		huawei,vcmpd_valid = <0>;

        gpios = <&gpio12 7 0 &gpio12 5 0 &gpio12 3 0 &gpio12 4 0 &gpio12 2 0 &gpio12 1 0 &gpio11 6 0 &gpio12 0 0 &gpio11 7 0 &gpio12 6 0>;
        huawei,gpio-ctrl-types = "reset", "powerdown", "dphy_txrxz", "dphy_rstzcal", "cam_1v05_en", "cam_1v2_en", "cam_1v8_en", "cam_2v85_en", "cam_vcm_2v85_en", "cam_vcm_power";
		status = "ok";
	};
	&huawei_imx214 {
		huawei,is_fpga = <1>;
		gpios = <&gpio11 3 0 &gpio11 1 0 &gpio10 7 0 &gpio11 0 0 &gpio10 6 0 &gpio10 5 0 &gpio10 2 0 &gpio10 4 0 &gpio10 3 0 &gpio11 2 0>;
		huawei,gpio-ctrl-types = "reset", "powerdown", "dphy_txrxz", "dphy_rstzcal", "cam_1v05_en", "cam_1v2_en", "cam_1v8_en", "cam_2v85_en", "cam_vcm_2v85_en", "cam_vcm_power";
		status = "disable";
	};

	&huawei_imx230 {
		huawei,is_fpga = <1>;
		huawei,csi_index = <0 2>;
		huawei,i2c_index = <0 2>;
		gpios = <&gpio11 3 0 &gpio11 1 0 &gpio10 7 0 &gpio11 0 0 &gpio10 6 0 &gpio10 5 0 &gpio10 2 0 &gpio10 4 0 &gpio10 3 0 &gpio11 2 0>;
		huawei,gpio-ctrl-types = "reset", "powerdown", "dphy_txrxz", "dphy_rstzcal", "cam_1v05_en", "cam_1v2_en", "cam_1v8_en", "cam_2v85_en", "cam_vcm_2v85_en", "cam_vcm_power";
		status = "disable";
    };

	&huawei_imx298 {
		huawei,is_fpga = <1>;
		huawei,csi_index = <0 2>;
		huawei,i2c_index = <0 2>;
		gpios = <&gpio11 3 0 &gpio11 1 0 &gpio10 7 0 &gpio11 0 0 &gpio10 6 0 &gpio10 5 0 &gpio10 2 0 &gpio10 4 0 &gpio10 3 0 &gpio11 2 0>;
		huawei,gpio-ctrl-types = "reset", "powerdown", "dphy_txrxz", "dphy_rstzcal", "cam_1v05_en", "cam_1v2_en", "cam_1v8_en", "cam_2v85_en", "cam_vcm_2v85_en", "cam_vcm_power";
		status = "disable";
	};

	&huawei_imx286dual{
		compatible = "huawei,imx286dual_udp";
		huawei,sensor_name = "IMX286DUAL";
		huawei,sensor_index = <0>;
		huawei,is_fpga = <1>;
		huawei,pd_valid = <1>;
		huawei,reset_valid = <1>;
		huawei,vcmpd_valid = <0>;
		huawei,csi_index = <0 2>;
		huawei,i2c_index = <0 2>;
		gpios = <&gpio11 3 0 &gpio11 1 0 &gpio10 7 0 &gpio11 0 0 &gpio10 6 0 &gpio10 5 0 &gpio10 2 0 &gpio10 4 0 &gpio10 3 0 &gpio11 2 0>;
		huawei,gpio-ctrl-types = "reset", "powerdown", "dphy_txrxz", "dphy_rstzcal", "cam_1v05_en", "cam_1v2_en", "cam_1v8_en", "cam_2v85_en", "cam_vcm_2v85_en", "cam_vcm_power";
		status = "disable";
	};

	&huawei_imx278 {
		huawei,is_fpga = <1>;
		gpios = <&gpio11 3 0 &gpio11 1 0 &gpio10 7 0 &gpio11 0 0 &gpio10 6 0 &gpio10 5 0 &gpio10 2 0 &gpio10 4 0 &gpio10 3 0 &gpio11 2 0>;
		huawei,gpio-ctrl-types = "reset", "powerdown", "dphy_txrxz", "dphy_rstzcal", "cam_1v05_en", "cam_1v2_en", "cam_1v8_en", "cam_2v85_en", "cam_vcm_2v85_en", "cam_vcm_power";
		status = "disable";
	};

	&hisee {
		compatible = "hisilicon,hisee-device";
		cos_upgrade_time = <3000000>;
		is_fpga;
	};

	&pmu_a55 {
	};

	&pmu_a77 {
	};
	&dsu_pmu_0 {
	};

